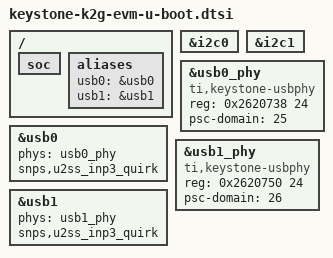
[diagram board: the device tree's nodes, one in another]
// SPDX-License-Identifier: GPL-2.0+
/*
 * Copyright (C) 2017 Texas Instruments Incorporated - https://www.ti.com/
 */

/{
	soc {
		bootph-all;
	};
	aliases {
		usb0 = &usb0;
		usb1 = &usb1;
	};
};

&i2c0 {
	bootph-all;
};

&i2c1 {
	bootph-all;
};

&usb0_phy {
	compatible = "ti,keystone-usbphy";
	#phy-cells = <0>;
	reg = <0x2620738 24>;
	psc-domain = <25>;
};

&usb0 {
	phys = <&usb0_phy>;
	snps,u2ss_inp3_quirk;
};

&usb1_phy {
	compatible = "ti,keystone-usbphy";
	#phy-cells = <0>;
	reg = <0x2620750 24>;
	psc-domain = <26>;
};

&usb1 {
	phys = <&usb1_phy>;
	snps,u2ss_inp3_quirk;
};
